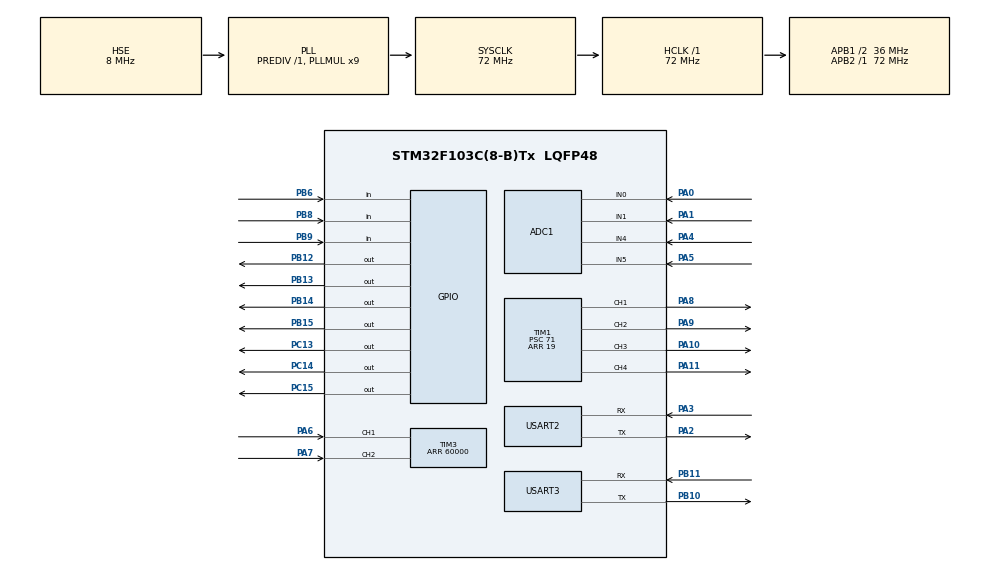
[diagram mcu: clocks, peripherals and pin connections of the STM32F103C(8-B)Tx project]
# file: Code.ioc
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ADC1.Channel-0\#ChannelRegularConversion=ADC_CHANNEL_0
ADC1.Channel-1\#ChannelRegularConversion=ADC_CHANNEL_1
ADC1.Channel-2\#ChannelRegularConversion=ADC_CHANNEL_4
ADC1.Channel-3\#ChannelRegularConversion=ADC_CHANNEL_5
ADC1.ContinuousConvMode=DISABLE
ADC1.NbrOfConversion=4
ADC1.NbrOfConversionFlag=1
ADC1.Rank-0\#ChannelRegularConversion=1
ADC1.Rank-1\#ChannelRegularConversion=2
ADC1.Rank-2\#ChannelRegularConversion=3
ADC1.Rank-3\#ChannelRegularConversion=4
ADC1.SamplingTime-0\#ChannelRegularConversion=ADC_SAMPLETIME_1CYCLE_5
ADC1.SamplingTime-1\#ChannelRegularConversion=ADC_SAMPLETIME_1CYCLE_5
ADC1.SamplingTime-2\#ChannelRegularConversion=ADC_SAMPLETIME_1CYCLE_5
ADC1.SamplingTime-3\#ChannelRegularConversion=ADC_SAMPLETIME_1CYCLE_5
ADC1.master=1
Dma.ADC1.0.Direction=DMA_PERIPH_TO_MEMORY
Dma.ADC1.0.Instance=DMA1_Channel1
Dma.ADC1.0.MemDataAlignment=DMA_MDATAALIGN_HALFWORD
Dma.ADC1.0.MemInc=DMA_MINC_ENABLE
Dma.ADC1.0.Mode=DMA_CIRCULAR
Dma.ADC1.0.PeriphDataAlignment=DMA_PDATAALIGN_HALFWORD
Dma.ADC1.0.PeriphInc=DMA_PINC_DISABLE
Dma.ADC1.0.Priority=DMA_PRIORITY_LOW
Dma.Request0=ADC1
Mcu.Family=STM32F1
Mcu.Name=STM32F103C(8-B)Tx
Mcu.Package=LQFP48
NVIC.ADC1_2_IRQn=true\:1\:0\:true\:false\:true\:true\:true\:true
NVIC.DMA1_Channel1_IRQn=true\:0\:0\:false\:false\:true\:false\:true\:true
NVIC.PriorityGroup=NVIC_PRIORITYGROUP_4
NVIC.USART2_IRQn=true\:0\:0\:true\:false\:true\:true\:true\:true
PA0-WKUP.Signal=ADCx_IN0
PA1.Signal=ADCx_IN1
PA10.Signal=S_TIM1_CH3
PA11.Signal=S_TIM1_CH4
PA13.Mode=Serial_Wire
PA13.Signal=SYS_JTMS-SWDIO
PA14.Mode=Serial_Wire
PA14.Signal=SYS_JTCK-SWCLK
PA2.Mode=Asynchronous
PA2.Signal=USART2_TX
PA3.Mode=Asynchronous
PA3.Signal=USART2_RX
PA4.Signal=ADCx_IN4
PA5.Signal=ADCx_IN5
PA6.Signal=S_TIM3_CH1
PA7.Signal=S_TIM3_CH2
PA8.Signal=S_TIM1_CH1
PA9.Signal=S_TIM1_CH2
PB10.Mode=Asynchronous
PB10.Signal=USART3_TX
PB11.Mode=Asynchronous
PB11.Signal=USART3_RX
PB12.GPIO_PuPd=GPIO_NOPULL
PB12.GPIO_Speed=GPIO_SPEED_FREQ_HIGH
PB12.Signal=GPIO_Output
PB13.GPIO_PuPd=GPIO_NOPULL
PB13.GPIO_Speed=GPIO_SPEED_FREQ_HIGH
PB13.Signal=GPIO_Output
PB14.GPIO_PuPd=GPIO_NOPULL
PB14.GPIO_Speed=GPIO_SPEED_FREQ_HIGH
PB14.Signal=GPIO_Output
PB15.GPIO_PuPd=GPIO_NOPULL
PB15.GPIO_Speed=GPIO_SPEED_FREQ_HIGH
PB15.Signal=GPIO_Output
PB6.GPIO_PuPd=GPIO_PULLUP
PB6.Signal=GPIO_Input
PB8.GPIO_PuPd=GPIO_PULLUP
PB8.Signal=GPIO_Input
PB9.GPIO_PuPd=GPIO_PULLUP
PB9.Signal=GPIO_Input
PC13-TAMPER-RTC.Signal=GPIO_Output
PC14-OSC32_IN.GPIO_ModeDefaultOutputPP=GPIO_MODE_OUTPUT_OD
PC14-OSC32_IN.GPIO_PuPd=GPIO_PULLUP
PC14-OSC32_IN.GPIO_Speed=GPIO_SPEED_FREQ_HIGH
PC14-OSC32_IN.Signal=GPIO_Output
PC15-OSC32_OUT.GPIO_ModeDefaultOutputPP=GPIO_MODE_OUTPUT_OD
PC15-OSC32_OUT.GPIO_PuPd=GPIO_PULLUP
PC15-OSC32_OUT.GPIO_Speed=GPIO_SPEED_FREQ_HIGH
PC15-OSC32_OUT.Signal=GPIO_Output
PD0-OSC_IN.Mode=HSE-External-Oscillator
PD0-OSC_IN.Signal=RCC_OSC_IN
PD1-OSC_OUT.Mode=HSE-External-Oscillator
PD1-OSC_OUT.Signal=RCC_OSC_OUT
ProjectManager.HeapSize=0x200
ProjectManager.StackSize=0x400
ProjectManager.TargetToolchain=MDK-ARM V5.32
RCC.ADCPresc=RCC_ADCPCLK2_DIV6
RCC.AHBFreq_Value=72000000
RCC.APB1CLKDivider=RCC_HCLK_DIV2
RCC.APB1Freq_Value=36000000
RCC.APB1TimFreq_Value=72000000
RCC.APB2Freq_Value=72000000
RCC.APB2TimFreq_Value=72000000
RCC.HCLKFreq_Value=72000000
RCC.PLLMUL=RCC_PLL_MUL9
RCC.PLLSourceVirtual=RCC_PLLSOURCE_HSE
RCC.SYSCLKFreq_VALUE=72000000
RCC.SYSCLKSource=RCC_SYSCLKSOURCE_PLLCLK
RCC.TimSys_Div=SYSTICK_CLKSOURCE_HCLK_DIV8
RCC.USBFreq_Value=72000000
SH.ADCx_IN0.0=ADC1_IN0,IN0
SH.ADCx_IN1.0=ADC1_IN1,IN1
SH.ADCx_IN4.0=ADC1_IN4,IN4
SH.ADCx_IN5.0=ADC1_IN5,IN5
SH.S_TIM1_CH1.0=TIM1_CH1,PWM Generation1 CH1
SH.S_TIM1_CH2.0=TIM1_CH2,PWM Generation2 CH2
SH.S_TIM1_CH3.0=TIM1_CH3,PWM Generation3 CH3
SH.S_TIM1_CH4.0=TIM1_CH4,PWM Generation4 CH4
SH.S_TIM3_CH1.0=TIM3_CH1,Encoder_Interface
SH.S_TIM3_CH2.0=TIM3_CH2,Encoder_Interface
TIM1.Channel-PWM\ Generation1\ CH1=TIM_CHANNEL_1
TIM1.Channel-PWM\ Generation2\ CH2=TIM_CHANNEL_2
TIM1.Channel-PWM\ Generation3\ CH3=TIM_CHANNEL_3
TIM1.Channel-PWM\ Generation4\ CH4=TIM_CHANNEL_4
TIM1.Period=19
TIM1.Prescaler=71
TIM3.Period=60000
USART2.VirtualMode=VM_ASYNC
USART3.VirtualMode=VM_ASYNC
board=custom

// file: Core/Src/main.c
/* USER CODE BEGIN Header */
/**
  ******************************************************************************
  * @file           : main.c
  * @brief          : Main program body
  ******************************************************************************
  * @attention
  *
  * Copyright (c) 2024 STMicroelectronics.
  * All rights reserved.
  *
  * This software is licensed under terms that can be found in the LICENSE file
  * in the root directory of this software component.
  * If no LICENSE file comes with this software, it is provided AS-IS.
  *
  ******************************************************************************
  */
/* USER CODE END Header */
#include "main.h"

/* USER CODE BEGIN Includes */
#include "delay.h"
#include "DeskBoard.h"
/* USER CODE END Includes */

ADC_HandleTypeDef hadc1;
DMA_HandleTypeDef hdma_adc1;

TIM_HandleTypeDef htim1;
TIM_HandleTypeDef htim3;

UART_HandleTypeDef huart2;
UART_HandleTypeDef huart3;

void SystemClock_Config(void);
static void MX_GPIO_Init(void);
static void MX_DMA_Init(void);
static void MX_ADC1_Init(void);
static void MX_TIM1_Init(void);
static void MX_TIM3_Init(void);
static void MX_USART2_UART_Init(void);
static void MX_USART3_UART_Init(void);

/* USER CODE BEGIN 0 */
		float pitch,roll,yaw; 		    //欧拉角
    short aacx,aacy,aacz;			//加速度传感器原始数据
    short gyrox,gyroy,gyroz;		//陀螺仪原始数据
    float temp;					    //温度
/* USER CODE END 0 */

int main(void)
{

  /* MCU Configuration--------------------------------------------------------*/

  /* Reset of all peripherals, Initializes the Flash interface and the Systick. */
  HAL_Init();

  /* Configure the system clock */
  SystemClock_Config();

  /* Initialize all configured peripherals */
  MX_GPIO_Init();
  MX_DMA_Init();
  MX_ADC1_Init();
  MX_TIM1_Init();
  MX_TIM3_Init();
  MX_USART2_UART_Init();
  MX_USART3_UART_Init();
  /* USER CODE BEGIN 2 */
	HAL_GPIO_WritePin(GPIOC,GPIO_PIN_13,GPIO_PIN_SET);
	SysInit();
	ParamInit();
	DevInit();
	HAL_GPIO_WritePin(GPIOC,GPIO_PIN_13,GPIO_PIN_RESET);
//		MPU6050_initialize();			//MPU6050初始化
//    DMP_Init();		//dmp初始化
  /* USER CODE END 2 */

  /* Infinite loop */
  /* USER CODE BEGIN WHILE */
  while (1)
  {

		GetData();
		Control();
//		HAL_GPIO_WritePin(GPIOB,GPIO_PIN_8,GPIO_PIN_SET);

    /* USER CODE END WHILE */

  }
}

void SystemClock_Config(void)
{
  RCC_OscInitTypeDef RCC_OscInitStruct = {0};
  RCC_ClkInitTypeDef RCC_ClkInitStruct = {0};
  RCC_PeriphCLKInitTypeDef PeriphClkInit = {0};

  /** Initializes the RCC Oscillators according to the specified parameters
  * in the RCC_OscInitTypeDef structure.
  */
  RCC_OscInitStruct.OscillatorType = RCC_OSCILLATORTYPE_HSE;
  RCC_OscInitStruct.HSEState = RCC_HSE_ON;
  RCC_OscInitStruct.HSEPredivValue = RCC_HSE_PREDIV_DIV1;
  RCC_OscInitStruct.HSIState = RCC_HSI_ON;
  RCC_OscInitStruct.PLL.PLLState = RCC_PLL_ON;
  RCC_OscInitStruct.PLL.PLLSource = RCC_PLLSOURCE_HSE;
  RCC_OscInitStruct.PLL.PLLMUL = RCC_PLL_MUL9;
  if (HAL_RCC_OscConfig(&RCC_OscInitStruct) != HAL_OK)
  {
    Error_Handler();
  }

  /** Initializes the CPU, AHB and APB buses clocks
  */
  RCC_ClkInitStruct.ClockType = RCC_CLOCKTYPE_HCLK|RCC_CLOCKTYPE_SYSCLK
                              |RCC_CLOCKTYPE_PCLK1|RCC_CLOCKTYPE_PCLK2;
  RCC_ClkInitStruct.SYSCLKSource = RCC_SYSCLKSOURCE_PLLCLK;
  RCC_ClkInitStruct.AHBCLKDivider = RCC_SYSCLK_DIV1;
  RCC_ClkInitStruct.APB1CLKDivider = RCC_HCLK_DIV2;
  RCC_ClkInitStruct.APB2CLKDivider = RCC_HCLK_DIV1;

  if (HAL_RCC_ClockConfig(&RCC_ClkInitStruct, FLASH_LATENCY_2) != HAL_OK)
  {
    Error_Handler();
  }
  PeriphClkInit.PeriphClockSelection = RCC_PERIPHCLK_ADC;
  PeriphClkInit.AdcClockSelection = RCC_ADCPCLK2_DIV6;
  if (HAL_RCCEx_PeriphCLKConfig(&PeriphClkInit) != HAL_OK)
  {
    Error_Handler();
  }
}

static void MX_ADC1_Init(void)
{

  ADC_ChannelConfTypeDef sConfig = {0};

  /** Common config
  */
  hadc1.Instance = ADC1;
  hadc1.Init.ScanConvMode = ADC_SCAN_ENABLE;
  hadc1.Init.ContinuousConvMode = DISABLE;
  hadc1.Init.DiscontinuousConvMode = DISABLE;
  hadc1.Init.ExternalTrigConv = ADC_SOFTWARE_START;
  hadc1.Init.DataAlign = ADC_DATAALIGN_RIGHT;
  hadc1.Init.NbrOfConversion = 4;
  if (HAL_ADC_Init(&hadc1) != HAL_OK)
  {
    Error_Handler();
  }

  /** Configure Regular Channel
  */
  sConfig.Channel = ADC_CHANNEL_0;
  sConfig.Rank = ADC_REGULAR_RANK_1;
  sConfig.SamplingTime = ADC_SAMPLETIME_1CYCLE_5;
  if (HAL_ADC_ConfigChannel(&hadc1, &sConfig) != HAL_OK)
  {
    Error_Handler();
  }

  /** Configure Regular Channel
  */
  sConfig.Channel = ADC_CHANNEL_1;
  sConfig.Rank = ADC_REGULAR_RANK_2;
  if (HAL_ADC_ConfigChannel(&hadc1, &sConfig) != HAL_OK)
  {
    Error_Handler();
  }

  /** Configure Regular Channel
  */
  sConfig.Channel = ADC_CHANNEL_4;
  sConfig.Rank = ADC_REGULAR_RANK_3;
  if (HAL_ADC_ConfigChannel(&hadc1, &sConfig) != HAL_OK)
  {
    Error_Handler();
  }

  /** Configure Regular Channel
  */
  sConfig.Channel = ADC_CHANNEL_5;
  sConfig.Rank = ADC_REGULAR_RANK_4;
  if (HAL_ADC_ConfigChannel(&hadc1, &sConfig) != HAL_OK)
  {
    Error_Handler();
  }

}

static void MX_TIM1_Init(void)
{

  TIM_MasterConfigTypeDef sMasterConfig = {0};
  TIM_OC_InitTypeDef sConfigOC = {0};
  TIM_BreakDeadTimeConfigTypeDef sBreakDeadTimeConfig = {0};

  htim1.Instance = TIM1;
  htim1.Init.Prescaler = 71;
  htim1.Init.CounterMode = TIM_COUNTERMODE_UP;
  htim1.Init.Period = 19;
  htim1.Init.ClockDivision = TIM_CLOCKDIVISION_DIV1;
  htim1.Init.RepetitionCounter = 0;
  htim1.Init.AutoReloadPreload = TIM_AUTORELOAD_PRELOAD_DISABLE;
  if (HAL_TIM_PWM_Init(&htim1) != HAL_OK)
  {
    Error_Handler();
  }
  sMasterConfig.MasterOutputTrigger = TIM_TRGO_RESET;
  sMasterConfig.MasterSlaveMode = TIM_MASTERSLAVEMODE_DISABLE;
  if (HAL_TIMEx_MasterConfigSynchronization(&htim1, &sMasterConfig) != HAL_OK)
  {
    Error_Handler();
  }
  sConfigOC.OCMode = TIM_OCMODE_PWM1;
  sConfigOC.Pulse = 0;
  sConfigOC.OCPolarity = TIM_OCPOLARITY_HIGH;
  sConfigOC.OCNPolarity = TIM_OCNPOLARITY_HIGH;
  sConfigOC.OCFastMode = TIM_OCFAST_DISABLE;
  sConfigOC.OCIdleState = TIM_OCIDLESTATE_RESET;
  sConfigOC.OCNIdleState = TIM_OCNIDLESTATE_RESET;
  if (HAL_TIM_PWM_ConfigChannel(&htim1, &sConfigOC, TIM_CHANNEL_1) != HAL_OK)
  {
    Error_Handler();
  }
  if (HAL_TIM_PWM_ConfigChannel(&htim1, &sConfigOC, TIM_CHANNEL_2) != HAL_OK)
  {
    Error_Handler();
  }
  if (HAL_TIM_PWM_ConfigChannel(&htim1, &sConfigOC, TIM_CHANNEL_3) != HAL_OK)
  {
    Error_Handler();
  }
  if (HAL_TIM_PWM_ConfigChannel(&htim1, &sConfigOC, TIM_CHANNEL_4) != HAL_OK)
  {
    Error_Handler();
  }
  sBreakDeadTimeConfig.OffStateRunMode = TIM_OSSR_DISABLE;
  sBreakDeadTimeConfig.OffStateIDLEMode = TIM_OSSI_DISABLE;
  sBreakDeadTimeConfig.LockLevel = TIM_LOCKLEVEL_OFF;
  sBreakDeadTimeConfig.DeadTime = 0;
  sBreakDeadTimeConfig.BreakState = TIM_BREAK_DISABLE;
  sBreakDeadTimeConfig.BreakPolarity = TIM_BREAKPOLARITY_HIGH;
  sBreakDeadTimeConfig.AutomaticOutput = TIM_AUTOMATICOUTPUT_DISABLE;
  if (HAL_TIMEx_ConfigBreakDeadTime(&htim1, &sBreakDeadTimeConfig) != HAL_OK)
  {
    Error_Handler();
  }
  HAL_TIM_MspPostInit(&htim1);

}

static void MX_TIM3_Init(void)
{

  TIM_Encoder_InitTypeDef sConfig = {0};
  TIM_MasterConfigTypeDef sMasterConfig = {0};

  htim3.Instance = TIM3;
  htim3.Init.Prescaler = 0;
  htim3.Init.CounterMode = TIM_COUNTERMODE_UP;
  htim3.Init.Period = 60000;
  htim3.Init.ClockDivision = TIM_CLOCKDIVISION_DIV1;
  htim3.Init.AutoReloadPreload = TIM_AUTORELOAD_PRELOAD_DISABLE;
  sConfig.EncoderMode = TIM_ENCODERMODE_TI1;
  sConfig.IC1Polarity = TIM_ICPOLARITY_RISING;
  sConfig.IC1Selection = TIM_ICSELECTION_DIRECTTI;
  sConfig.IC1Prescaler = TIM_ICPSC_DIV1;
  sConfig.IC1Filter = 0;
  sConfig.IC2Polarity = TIM_ICPOLARITY_RISING;
  sConfig.IC2Selection = TIM_ICSELECTION_DIRECTTI;
  sConfig.IC2Prescaler = TIM_ICPSC_DIV1;
  sConfig.IC2Filter = 0;
  if (HAL_TIM_Encoder_Init(&htim3, &sConfig) != HAL_OK)
  {
    Error_Handler();
  }
  sMasterConfig.MasterOutputTrigger = TIM_TRGO_RESET;
  sMasterConfig.MasterSlaveMode = TIM_MASTERSLAVEMODE_DISABLE;
  if (HAL_TIMEx_MasterConfigSynchronization(&htim3, &sMasterConfig) != HAL_OK)
  {
    Error_Handler();
  }

}

static void MX_USART2_UART_Init(void)
{

  huart2.Instance = USART2;
  huart2.Init.BaudRate = 115200;
  huart2.Init.WordLength = UART_WORDLENGTH_8B;
  huart2.Init.StopBits = UART_STOPBITS_1;
  huart2.Init.Parity = UART_PARITY_NONE;
  huart2.Init.Mode = UART_MODE_TX_RX;
  huart2.Init.HwFlowCtl = UART_HWCONTROL_NONE;
  huart2.Init.OverSampling = UART_OVERSAMPLING_16;
  if (HAL_UART_Init(&huart2) != HAL_OK)
  {
    Error_Handler();
  }

}

static void MX_USART3_UART_Init(void)
{

  huart3.Instance = USART3;
  huart3.Init.BaudRate = 115200;
  huart3.Init.WordLength = UART_WORDLENGTH_8B;
  huart3.Init.StopBits = UART_STOPBITS_1;
  huart3.Init.Parity = UART_PARITY_NONE;
  huart3.Init.Mode = UART_MODE_TX_RX;
  huart3.Init.HwFlowCtl = UART_HWCONTROL_NONE;
  huart3.Init.OverSampling = UART_OVERSAMPLING_16;
  if (HAL_UART_Init(&huart3) != HAL_OK)
  {
    Error_Handler();
  }

}

static void MX_DMA_Init(void)
{

  /* DMA controller clock enable */
  __HAL_RCC_DMA1_CLK_ENABLE();

  /* DMA interrupt init */
  /* DMA1_Channel1_IRQn interrupt configuration */
  HAL_NVIC_SetPriority(DMA1_Channel1_IRQn, 0, 0);
  HAL_NVIC_EnableIRQ(DMA1_Channel1_IRQn);

}

static void MX_GPIO_Init(void)
{
  GPIO_InitTypeDef GPIO_InitStruct = {0};

  /* GPIO Ports Clock Enable */
  __HAL_RCC_GPIOC_CLK_ENABLE();
  __HAL_RCC_GPIOD_CLK_ENABLE();
  __HAL_RCC_GPIOA_CLK_ENABLE();
  __HAL_RCC_GPIOB_CLK_ENABLE();

  /*Configure GPIO pin Output Level */
  HAL_GPIO_WritePin(GPIOC, GPIO_PIN_13|GPIO_PIN_14|GPIO_PIN_15, GPIO_PIN_RESET);

  /*Configure GPIO pin Output Level */
  HAL_GPIO_WritePin(GPIOB, GPIO_PIN_12|GPIO_PIN_13|GPIO_PIN_14|GPIO_PIN_15, GPIO_PIN_RESET);

  /*Configure GPIO pin : PC13 */
  GPIO_InitStruct.Pin = GPIO_PIN_13;
  GPIO_InitStruct.Mode = GPIO_MODE_OUTPUT_PP;
  GPIO_InitStruct.Pull = GPIO_NOPULL;
  GPIO_InitStruct.Speed = GPIO_SPEED_FREQ_LOW;
  HAL_GPIO_Init(GPIOC, &GPIO_InitStruct);

  /*Configure GPIO pins : PC14 PC15 */
  GPIO_InitStruct.Pin = GPIO_PIN_14|GPIO_PIN_15;
  GPIO_InitStruct.Mode = GPIO_MODE_OUTPUT_OD;
  GPIO_InitStruct.Pull = GPIO_PULLUP;
  GPIO_InitStruct.Speed = GPIO_SPEED_FREQ_HIGH;
  HAL_GPIO_Init(GPIOC, &GPIO_InitStruct);

  /*Configure GPIO pins : PB12 PB13 PB14 PB15 */
  GPIO_InitStruct.Pin = GPIO_PIN_12|GPIO_PIN_13|GPIO_PIN_14|GPIO_PIN_15;
  GPIO_InitStruct.Mode = GPIO_MODE_OUTPUT_PP;
  GPIO_InitStruct.Pull = GPIO_NOPULL;
  GPIO_InitStruct.Speed = GPIO_SPEED_FREQ_HIGH;
  HAL_GPIO_Init(GPIOB, &GPIO_InitStruct);

  /*Configure GPIO pins : PB6 PB8 PB9 */
  GPIO_InitStruct.Pin = GPIO_PIN_6|GPIO_PIN_8|GPIO_PIN_9;
  GPIO_InitStruct.Mode = GPIO_MODE_INPUT;
  GPIO_InitStruct.Pull = GPIO_PULLUP;
  HAL_GPIO_Init(GPIOB, &GPIO_InitStruct);

}

void Error_Handler(void)
{
  __disable_irq();
  while (1)
  {
  }
}
